# STM32F412CEU6 register map
File version: 1.0
STM32F412CEU6,STM32F412CGU6,STM32F412RET6,STM32F412RET7,STM32F412REY6,STM32F412REY6P,STM32F412REY7,STM32F412REY7P,STM32F412RGT6,STM32F412RGY6,STM32F412RGY6P,STM32F412VEH3,STM32F412VEH6,STM32F412VEH7,STM32F412VET3,STM32F412VET6,STM32F412VET7,STM32F412VGH6,STM32F412VGH7,STM32F412VGT6,STM32F412VGT7,STM32F412ZEJ3,STM32F412ZEJ6,STM32F412ZEJ7,STM32F412ZET3,STM32F412ZET6,STM32F412ZET7,STM32F412ZGJ6,STM32F412ZGJ7,STM32F412ZGT6,STM32F412ZGT7
Registers are 32-bit, access not given, reset 0x0 unless marked. A register's access mark holds for its fields unless they carry their own. Offsets are from the block's base; lines under a group give offsets from that group; [hi:lo] are bit positions; {n}, {i} and the like mark numbered series; 'fields as' and 'values as' point back to an identical list; <NAME> marks a mode.

## Memory map
0x40000000 TIM2
0x40000400 TIM3
0x40000800 TIM4
0x40000C00 TIM5
0x40001000 TIM6
0x40001400 TIM7
0x40001800 TIM12
0x40001C00 TIM13
0x40002000 TIM14
0x40002800 BKP
0x40002800 RTC
0x40002C00 WWDG
0x40003000 IWDG
0x40003800 SPI2
0x40003C00 SPI3
0x40004400 USART2
0x40004800 USART3
0x40005400 I2C1
0x40005800 I2C2
0x40005C00 I2C3
0x40006000 I2CFMP1
0x40006400 CAN1
0x40006800 CAN2
0x40007000 PWR
0x40010000 TIM1
0x40010400 TIM8
0x40011000 USART1
0x40011400 USART6
0x40012000 ADC1
0x40012C00 SDIO
0x40013000 SPI1
0x40013400 SPI4
0x40013800 SYSCFG
0x40013C00 EXTI
0x40014000 TIM9
0x40014400 TIM10
0x40014800 TIM11
0x40015000 SPI5
0x40016000 DFSDM1
0x40020000 GPIOA
0x40020400 GPIOB
0x40020800 GPIOC
0x40020C00 GPIOD
0x40021000 GPIOE
0x40021400 GPIOF
0x40021800 GPIOG
0x40021C00 GPIOH
0x40023000 CRC
0x40023800 RCC
0x40023C00 FLASH
0x40026000 DMA1
0x40026400 DMA2
0x50000000 USB_OTG_FS
0x50060800 RNG
0x60000000 FSMC
0x90000000 QUADSPI
0xA0000000 FSMC
0xA0001000 QSPI

## TIM2
Base 0x40000000
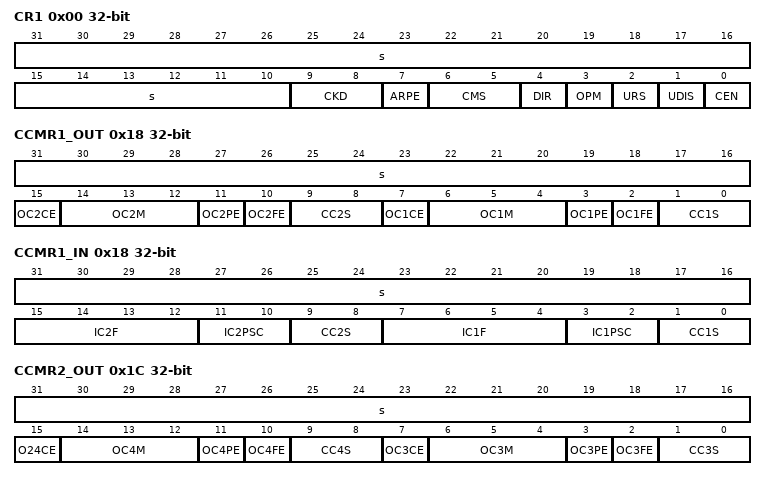
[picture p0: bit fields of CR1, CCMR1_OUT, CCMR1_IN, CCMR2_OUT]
0x00 CR1
  [31:10] s, [9:8] CKD, [7] ARPE, [6:5] CMS, [4] DIR, [3] OPM, [2] URS, [1] UDIS, [0] CEN
0x04 CR2
  [7] TI1S, [6:4] MMS, [3] CCDS, [31:0] s
0x08 SMCR
  [15] ETP, [14] ECE, [13:12] ETPS, [11:8] ETF, [7] MSM, [6:4] TS, [31:3] s, [2:0] SMS
0x0C DIER
  [14] TDE, [13] COMDE, [n+8] CC{n}DE (n=1..4), [8] UDE, [6] TIE, [31:5] s, [n] CC{n}IE (n=1..4), [0] UIE
0x10 SR
  [n+8] CC{n}OF (n=1..4), [6] TIF, [31:5] s, [n] CC{n}IF (n=1..4), [0] UIF
0x14 EGR
  [6] TG, [31:5] s, [n] CC{n}G (n=1..4), [0] UG
0x18 CCMR1_OUT
  [31:16] s, [15] OC2CE, [14:12] OC2M, [11] OC2PE, [10] OC2FE, [9:8] CC2S, [7] OC1CE, [6:4] OC1M, [3] OC1PE, [2] OC1FE, [1:0] CC1S
0x18 CCMR1_IN
  [31:16] s, [15:12] IC2F, [11:10] IC2PSC, [9:8] CC2S, [7:4] IC1F, [3:2] IC1PSC, [1:0] CC1S
0x1C CCMR2_OUT
  [31:16] s, [15] O24CE, [14:12] OC4M, [11] OC4PE, [10] OC4FE, [9:8] CC4S, [7] OC3CE, [6:4] OC3M, [3] OC3PE, [2] OC3FE, [1:0] CC3S
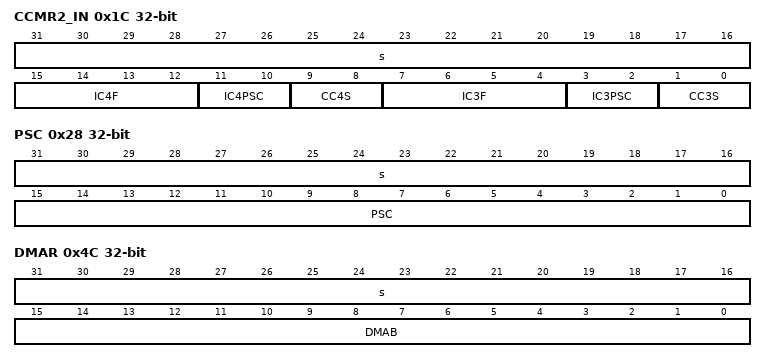
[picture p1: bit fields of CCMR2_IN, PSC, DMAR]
0x1C CCMR2_IN
  [31:16] s, [15:12] IC4F, [11:10] IC4PSC, [9:8] CC4S, [7:4] IC3F, [3:2] IC3PSC, [1:0] CC3S
0x20 CCER
  [4n-1] CC{n}NP (n=1..4), [4n-3] CC{n}P (n=1..4), [4n-4] CC{n}E (n=1..4), [31:2] s
0x24 CNT
0x28 PSC
  [31:16] s, [15:0] PSC
0x2C ARR
{0x30+4i} CCR{i} (i=1..4)
0x48 DCR
  [12:8] DBL, [31:5] s, [4:0] DBA
0x4C DMAR
  [31:16] s, [15:0] DMAB
0x50 OR
  [11:10] ITR1_RMP, [31:0] s

## TIM3
Base 0x40000400
Registers as TIM2, without OR.

## TIM4
Base 0x40000800
Registers as TIM2, without OR.

## TIM5
Base 0x40000C00
Registers as TIM2; these are added or differ:
0x50 OR
  [7:6] IT4_RMP, [31:0] s

## TIM6
Base 0x40001000
Same registers: TIM7 0x40001400
0x00 CR1
0x04 CR2
0x0C DIER
0x10 SR
0x14 EGR
0x24 CNT
0x28 PSC
0x2C ARR

## TIM12
Base 0x40001800
Same registers: TIM9 0x40014000
0x00 CR1
  [9:8] CKD, [7] ARPE, [31:4] s, [3] OPM, [2] URS, [1] UDIS, [0] CEN
0x08 SMCR
  [7] MSM, [6:4] TS, [31:3] s, [2:0] SMS
0x0C DIER
  [6] TIE, [31:3] s, [2] CC2IE, [1] CC1IE, [0] UIE
0x10 SR
  [10] CC2OF, [9] CC1OF, [6] TIF, [31:3] s, [2] CC2IF, [1] CC1IF, [0] UIF
0x14 EGR
  [6] TG, [31:3] s, [2] CC2G, [1] CC1G, [0] UG
0x18 CCMR1_OUT
  [14:12] OC2M, [11] OC2PE, [10] OC2FE, [9:8] CC2S, [31:7] s, [6:4] OC1M, [3] OC1PE, [2] OC1FE, [1:0] CC1S
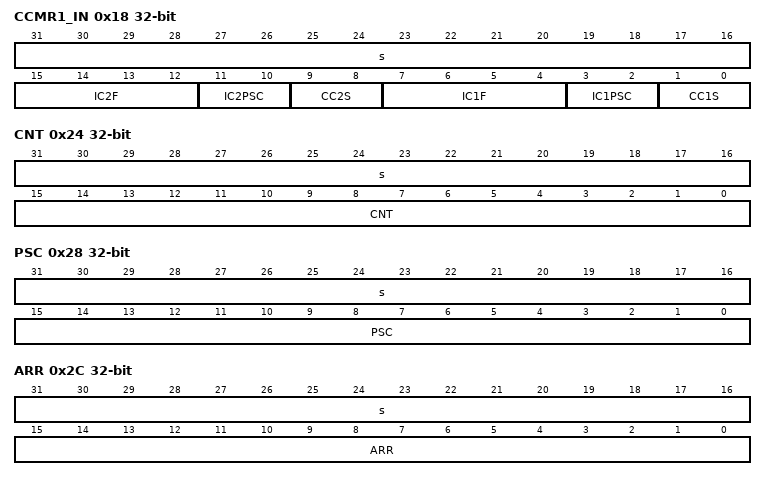
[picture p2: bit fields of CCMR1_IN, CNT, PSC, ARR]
0x18 CCMR1_IN
  [31:16] s, [15:12] IC2F, [11:10] IC2PSC, [9:8] CC2S, [7:4] IC1F, [3:2] IC1PSC, [1:0] CC1S
0x20 CCER
  [7] CC2NP, [5] CC2P, [4] CC2E, [3] CC1NP, [31:2] s, [1] CC1P, [0] CC1E
0x24 CNT
  [31:16] s, [15:0] CNT
0x28 PSC
  [31:16] s, [15:0] PSC
0x2C ARR
  [31:16] s, [15:0] ARR
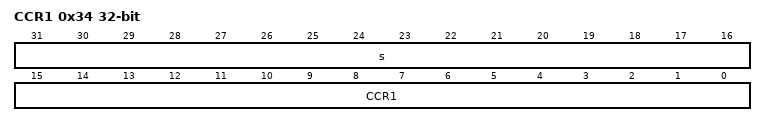
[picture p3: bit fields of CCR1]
0x34 CCR1
  [31:16] s, [15:0] CCR1
0x38 CCR2
